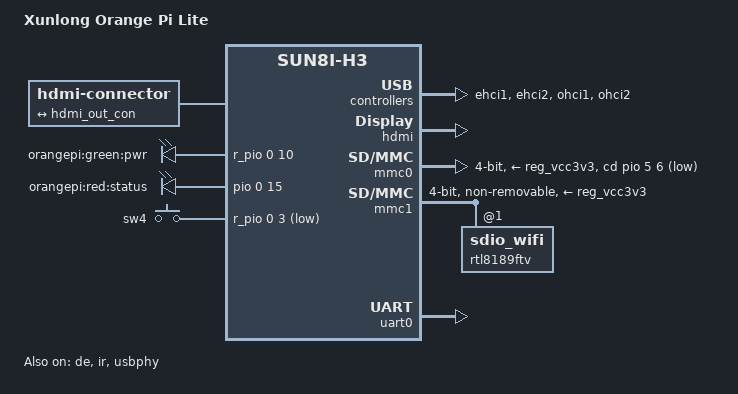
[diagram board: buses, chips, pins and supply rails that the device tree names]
/dts-v1/;
#include "sun8i-h3.dtsi"
#include "sunxi-common-regulators.dtsi"
#include <dt-bindings/gpio/gpio.h>
#include <dt-bindings/input/input.h>
/ {
	model = "Xunlong Orange Pi Lite";
	compatible = "xunlong,orangepi-lite", "allwinner,sun8i-h3";
	aliases {
		ethernet0 = &rtl8189ftv;
		serial0 = &uart0;
	};
	chosen {
		stdout-path = "serial0:115200n8";
	};
	connector {
		compatible = "hdmi-connector";
		type = "a";
		port {
			hdmi_con_in: endpoint {
				remote-endpoint = <&hdmi_out_con>;
			};
		};
	};
	leds {
		compatible = "gpio-leds";
		pwr_led {
			label = "orangepi:green:pwr";
			gpios = <&r_pio 0 10 GPIO_ACTIVE_HIGH>;
			default-state = "on";
		};
		status_led {
			label = "orangepi:red:status";
			gpios = <&pio 0 15 GPIO_ACTIVE_HIGH>;
		};
	};
	gpio-keys {
		compatible = "gpio-keys";
		switch-4 {
			label = "sw4";
			linux,code = <BTN_0>;
			gpios = <&r_pio 0 3 GPIO_ACTIVE_LOW>;
		};
	};
};
&de {
	status = "okay";
};
&ehci1 {
	status = "okay";
};
&ehci2 {
	status = "okay";
};
&hdmi {
	status = "okay";
};
&hdmi_out {
	hdmi_out_con: endpoint {
		remote-endpoint = <&hdmi_con_in>;
	};
};
&ir {
	pinctrl-names = "default";
	pinctrl-0 = <&r_ir_rx_pin>;
	status = "okay";
};
&mmc0 {
	vmmc-supply = <&reg_vcc3v3>;
	bus-width = <4>;
	cd-gpios = <&pio 5 6 GPIO_ACTIVE_LOW>;  
	status = "okay";
};
&mmc1 {
	vmmc-supply = <&reg_vcc3v3>;
	bus-width = <4>;
	non-removable;
	status = "okay";
	rtl8189ftv: sdio_wifi@1 {
		reg = <1>;
	};
};
&ohci1 {
	status = "okay";
};
&ohci2 {
	status = "okay";
};
&uart0 {
	pinctrl-names = "default";
	pinctrl-0 = <&uart0_pa_pins>;
	status = "okay";
};
&usbphy {
	status = "okay";
};
